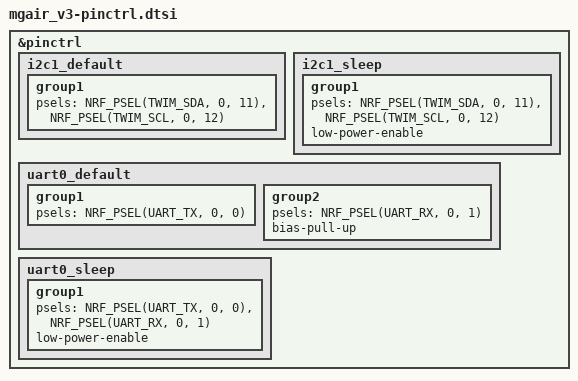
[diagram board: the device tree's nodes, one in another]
/*
 * Copyright (c) 2022 Nordic Semiconductor
 * SPDX-License-Identifier: Apache-2.0
 */

&pinctrl {
	i2c1_default: i2c1_default {
		group1 {
			psels = <NRF_PSEL(TWIM_SDA, 0, 11)>,
				<NRF_PSEL(TWIM_SCL, 0, 12)>;
		};
	};

	i2c1_sleep: i2c1_sleep {
		group1 {
			psels = <NRF_PSEL(TWIM_SDA, 0, 11)>,
				<NRF_PSEL(TWIM_SCL, 0, 12)>;
			low-power-enable;
		};
	};

	uart0_default: uart0_default {
		group1 {
			psels = <NRF_PSEL(UART_TX, 0, 0)>;
		};

		group2 {
			psels = <NRF_PSEL(UART_RX, 0, 1)>;
			bias-pull-up;
		};
	};

	uart0_sleep: uart0_sleep {
		group1 {
			psels = <NRF_PSEL(UART_TX, 0, 0)>,
					<NRF_PSEL(UART_RX, 0, 1)>;
			low-power-enable;
		};
	};
};
